# RN821X_RN721X_SOC_V3 register map
File version: v1.0.4
CPU: CM0 r0p0, little endian, no MPU, no FPU, 3 interrupt priority bits
Registers are 32-bit, read-write, reset 0x0 unless marked. A register's access mark holds for its fields unless they carry their own. Offsets are from the block's base; [hi:lo] are bit positions; {n}, {i} and the like mark numbered series; 'fields as' and 'values as' point back to an identical list.

## INTC — interrupt controller for off-chip interrupt requests
Base 0x40044000
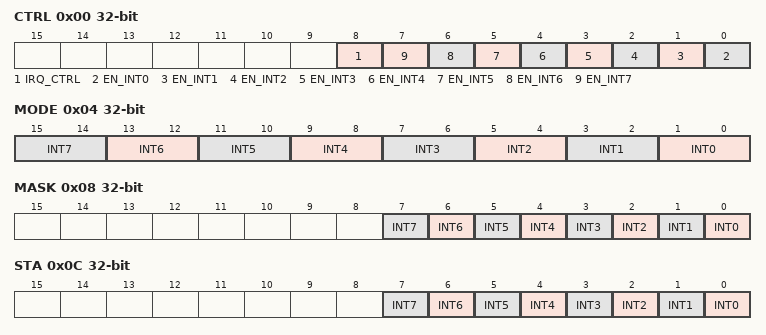
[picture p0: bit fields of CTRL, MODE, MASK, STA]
0x00 CTRL — INTC control register
  [8] IRQ_CTRL — external interrupt mode selection bit
    0=INDEP (INT0~INT7 independent control by INTC_CTRL[7:0]); 1=EXT0 (INT0~INT7 share EXT0 IRQ vector, check STA while interrupt occured)
  [n] EN_INT{n} (n=0..7) — external interrupt INT{n} module enable bit
0x04 MODE — INTC mode register
  [2n+1:2n] INT{n} (n=0..7) — external interrupt INT{n} mode selection bit
    0=PE (external interrupt INT{n} mode selection as posedge mode); 1=NE (external interrupt INT{n} mode selection as negedge mode); 2=BE (external interrupt INT{n} mode selection as both edge mode)
0x08 MASK — INTC mask register
  [n] INT{n} (n=0..7) — external interrupt INT{n} interrupt enable/disable bit
    0=DIS (external interrupt INT{n} interrupt disable); 1=EN (external interrupt INT{n} interrupt enable)
0x0C STA — Extern interrupt status register
  [all] fields
    0=NUL (external interrupt event not occured); 1=OCC (external interrupt event occured)
  [n] INT{n} write-1-clears (n=0..7) — external interrupt INT{n} status bit

## IOCNT — emu pulse forwarding module
Base 0x4006C000
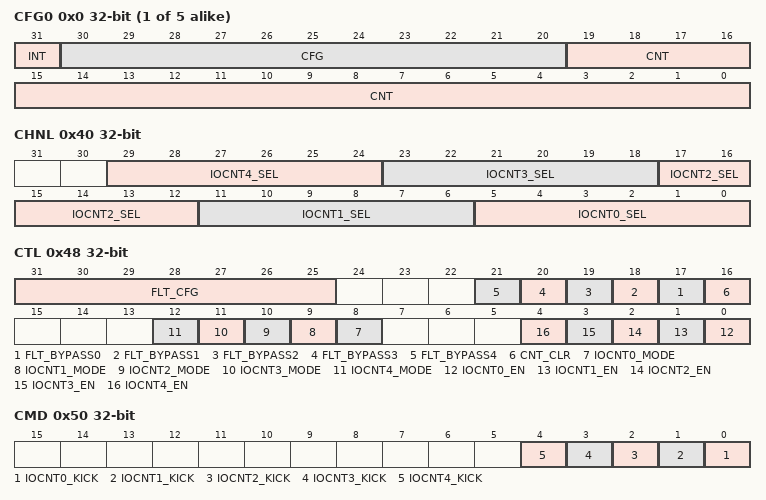
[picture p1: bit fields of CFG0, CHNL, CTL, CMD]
{0x0+4i} CFG{i} (i=0..4) — pulse forwarding configuration register{i+1}
  [31] INT — pluse inversion output enable bit
    0=NORM (output pulse level direction same as input pulse level); 1=INT (output pulse after it being inverted)
  [30:20] CFG — pluse freqency division configuration bits
  [19:0] CNT ro — pluse counter bits
{0x20+4i} OUT{i} (i=0..4) — pulse forwarding output counter register{i}
  [19:0] OUT{i} — pulse forwarding output counter bits
0x40 CHNL — pulse forwarding channel select register
  [6n+5:6n] IOCNT{n}_SEL (n=0..4) — IOCNT{n} input selection bits
0x48 CTL — pulse forwarding control register
  [31:25] FLT_CFG — IOCNT4~0 filter period config bits
  [n+17] FLT_BYPASS{n} (n=0..4) — IOCNT{n} FLT_BYPASS enable bit
  [16] CNT_CLR — pulse counter mode selection bit
  [n+8] IOCNT{n}_MODE (n=0..4) — IOCNT{n} count mode selection bit
  [n] IOCNT{n}_EN (n=0..4) — IOCNT{n} enable bit
0x4C CTL1 — pulse forwarding control register No.1
  [4:0] COPL — pulse forwarding config bits
0x50 CMD — pulse forwarding special command register
  [n] IOCNT{n}_KICK wo (n=0..4) — IOCNT{n} pulse forwarding special commond generation bit
{0x60+4i} REMD{i} ro (i=0..4) — input pulse remainder register No.1
  [10:0] REMD — input pulse remainder bits

## KBI — key detection
Base 0x40028000
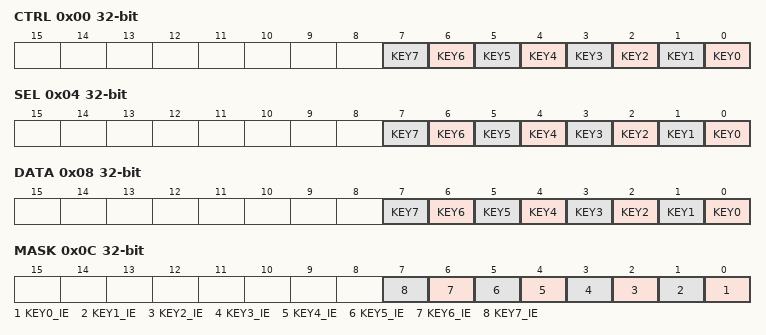
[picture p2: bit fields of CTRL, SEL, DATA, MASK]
0x00 CTRL — KBI control register
  [n] KEY{n} (n=0..7) — KBI KEY{n} enable/disable bit
    1=EN (KBI KEY{n} enable); 0=DIS (KBI KEY{n} disable)
0x04 SEL — KBI trigger mode select register
  [all] fields
    0=PE (KBI select posedge sampling); 1=NE (KBI select negedge sampling)
  [n] KEY{n} (n=0..7) — KBI KEY{n} posedge/negedge selection bit
0x08 DATA — KBI data register
  [all] fields
    1=PD (KEY pressed); 0=NUL (KEY not be pressed)
  [n] KEY{n} write-1-clears (n=0..7) — KBI KEY{n} data bit indicate key pressed or not
0x0C MASK — KBI interrupt mask register
  [n] KEY{n}_IE (n=0..7) — KBI KEY{n} interrupt enable/disable bit

## NVM — no voltage module
Base 0x40040000
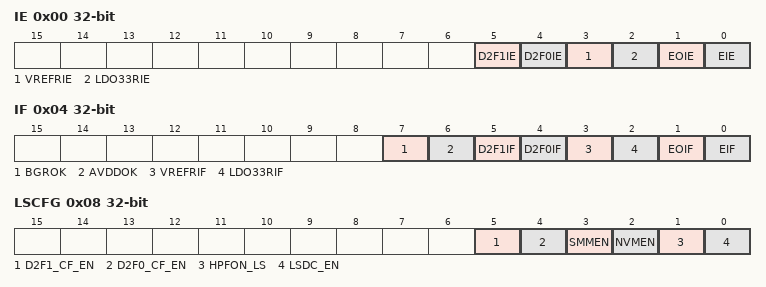
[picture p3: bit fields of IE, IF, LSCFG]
0x00 IE — interrupt enables
  [5] D2F1IE — d2f1 pulse interrupt enable
    0=DIS (do not generate interrupt when d2f1 pulse is output); 1=EN (generate interrupt when d2f1 pulse is output)
  [4] D2F0IE — d2f0 pulse interrupt enable
    0=DIS (do not generate interrupt when d2f0 pulse is output); 1=EN (generate interrupt when d2f0 pulse is output)
  [3] VREFRIE — VREF reset interrupt enable
    0=DIS (do not generate interrupt when VREF reset found); 1=EN (generate interrupt when VREF reset found)
  [2] LDO33RIE — LDO33 reset interrupt enable
    0=DIS (do not generate interrupt when reset found in LDO33 power domain); 1=EN (generate interrupt when reset found in LDO33 power domain)
  [1] EOIE — NV end and overflow interrupt enable
    0=DIS (do not generate interrupt when NV computation ends and NV value beyond threshold); 1=EN (generate interrupt when NV computation ends and NV value beyond threshold)
  [0] EIE — NV end interrupt enable
    0=DIS (do not generate interrupt when NV computation ends); 1=EN (generate interrupt when NV computation ends)
0x04 IF — interrupt flag
  [7] BGROK — bgr power ok
    0=NULL (power not ok); 1=OK (power ok)
  [6] AVDDOK — avdd power ok
    0=NULL (power not ok); 1=OK (power ok)
  [5] D2F1IF — d2f1 impulse interrupt flag
    0=NULL (no pending event of d2f1 impulse); 1=OCC (pending event of d2f1 impulse interrupt flag)
  [4] D2F0IF — d2f0 impulse interrupt flag
    0=NULL (no pending event of d2f0 impulse); 1=OCC (pending event of d2f0 impulse interrupt flag)
  [3] VREFRIF — VREF reset interrupt flag
    0=NULL (no pending event of VREF domain reset); 1=OCC (pending event of VREF domain reset found)
  [2] LDO33RIF — LDO33 reset interrupt flag
    0=NULL (no pending event of LDO33 power domain reset); 1=OCC (pending event of LDO33 power domain reset found)
  [1] EOIF — NV end and overflow interrupt flag
    0=NULL (no pending event of NV computation ends and NV value beyond threshold); 1=OCC (pending event of NV computation ends and NV value beyond threshold found)
  [0] EIF — NV end interrupt flag
    values as EOIF
0x08 LSCFG — NV config
  [5] D2F1_CF_EN — SMM enable
    0=DIS (D2F1 pulse not output to io); 1=EN (D2F1 pulse output to io)
  [4] D2F0_CF_EN — SMM enable
    0=DIS; 1=EN
  [3] SMMEN — SMM enable
    0=DIS (RMS updated every 20ms); 1=EN (RMS updated every 80ms)
  [2] NVMEN — module enable
    0=DIS (disabled); 1=EN (enabled)
  [1] HPFON_LS — high pass filter enable
    0=DIS (disabled); 1=EN (enabled)
  [0] LSDC_EN — automatic DC offset calibration enable
    0=DIS (disabled); 1=EN (enabled)
0x0C LSDCOS — NV measurement DC offset.
  [23:0] LSDCOS
0x10 LSTHO — NV measurement threshold
  [23:0] LSTHO
0x14 LSRMS ro — IA cyclic updated NV measurement RMS
  [23:0] LSRMS
0x18 LSRMS1 ro — IA RMS_L1 will not change after calculation
  [23:0] LSRMS1
0x20 HFCONST — HF const value
  [15:0] HFCONST
0x24 D2FP0 — D2F power 0 vaule
  [23:0] D2FP0
0x28 D2FP1 — D2F power 1 vaule
  [23:0] D2FP1

## SIMP_TC0 — simple tc
Base 0x40060000
Same registers: SIMP_TC1 0x4006000C, SIMP_TC2 0x40060018, SIMP_TC3 0x40060024
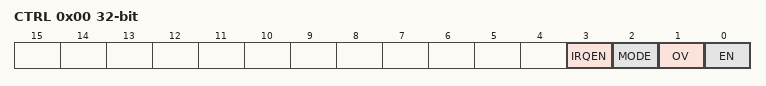
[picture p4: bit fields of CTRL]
0x00 CTRL — SIMP_TC control register
  [3] IRQEN — SIMP_TC interrupt enable bit
  [2] MODE — SIMP_TC count mode selection bit
    0=SINGLE (SIMP_TC select as single pulse mode); 1=REPETITIVE (SIMP_TC select as repetitive pulse mode)
  [1] OV write-1-clears — SIMP_TC overflow flag
  [0] EN — SIMP_TC enable bit
0x04 LOAD — SIMP_TC target counter register
  [31:0] LOAD — SIMP_TC target counting value setting bits
0x08 VAL — SIMP_TC counter register bits
  [31:0] VAL — SIMP_TC current count register bits

## WDT — watchdog timer
Base 0x40030000
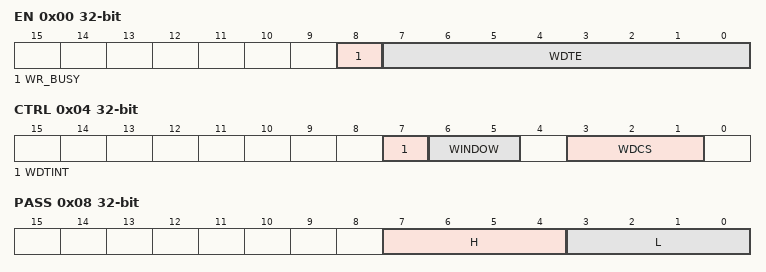
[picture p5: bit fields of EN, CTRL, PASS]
0x00 EN — Watchdog enable register
  [8] WR_BUSY ro — WDT write busy flag
  [7:0] WDTE — WDT enable bits
    187=RESTART (clear WDT counter and restart WDT(write value)); 85=DIS_DFLT (WDTE default value)
0x04 CTRL — WDT control register
  [7] WDTINT — WDT Timer Interval Interrupt
  [6:5] WINDOW — WDT Window Open Period
  [3:1] WDCS — WDT overflow time config
0x08 PASS — WDT password register
  [7:4] H ro — WDT high part password
  [3:0] L — WDT low part password
0x14 HALT — WDT HALT control register
  [15:0] EN — HALT_EN config bits
0x18 STBY — WDT STBY control register
  [15:0] EN — STBY_EN config bits
